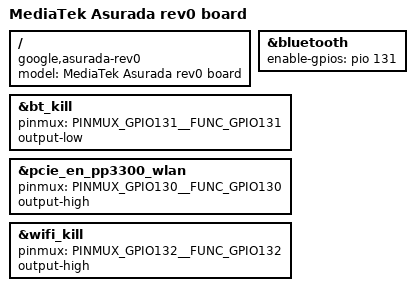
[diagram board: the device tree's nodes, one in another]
// SPDX-License-Identifier: (GPL-2.0 OR MIT)
/*
 * Copyright 2020 Google LLC
 */
/dts-v1/;
#include "mt8192-asurada.dtsi"

/ {
	model = "MediaTek Asurada rev0 board";
	compatible = "google,asurada-rev0";
};

&bluetooth {
	enable-gpios = <&pio 131 GPIO_ACTIVE_HIGH>;
};

&bt_kill {
	pinmux = <PINMUX_GPIO131__FUNC_GPIO131>; /* BT_KILL_L */
	output-low;
};

&pcie_en_pp3300_wlan {
	/* TODO: Model as a regulator */
	pinmux = <PINMUX_GPIO130__FUNC_GPIO130>;
	output-high;
};

/* TODO: Split and implement. */
&wifi_kill {
	pinmux = <PINMUX_GPIO132__FUNC_GPIO132>; /* WIFI_KILL_L */
	output-high;
};
